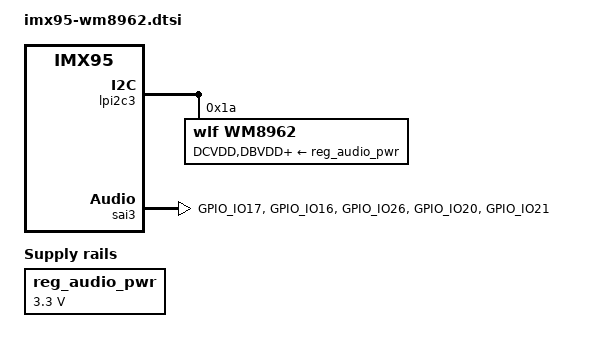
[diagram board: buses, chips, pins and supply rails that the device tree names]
&{/} {

	reg_audio_pwr: regulator-audio-pwr {
		compatible = "regulator-fixed";
		regulator-name = "audio-pwr";
		regulator-min-microvolt = <3300000>;
		regulator-max-microvolt = <3300000>;
	};

	sound-wm8962 {
		compatible = "fsl,imx-audio-wm8962x";
		model = "wm8962-audio";
		audio-cpu = <&sai3>;
		audio-codec = <&wm8962>;

		audio-routing =
			"Headphone Jack", "HPOUTL",
			"Headphone Jack", "HPOUTR",
			"Ext Spk", "SPKOUTL",
			"Ext Spk", "SPKOUTR",
			"AMIC", "MICBIAS",
			"IN3R", "AMIC",
			"IN1R", "AMIC";
	};
};

&lpi2c3 {
	#address-cells = <1>;
	#size-cells = <0>;

	wm8962: codec@1a {
		compatible = "wlf,wm8962";
		reg = <0x1a>;
		clocks = <&scmi_clk IMX95_CLK_SAI3>;
		DCVDD-supply = <&reg_audio_pwr>;
		DBVDD-supply = <&reg_audio_pwr>;
		AVDD-supply = <&reg_audio_pwr>;
		CPVDD-supply = <&reg_audio_pwr>;
		MICVDD-supply = <&reg_audio_pwr>;
		PLLVDD-supply = <&reg_audio_pwr>;
		SPKVDD1-supply = <&reg_audio_pwr>;
		SPKVDD2-supply = <&reg_audio_pwr>;
		gpio-cfg = <
			0x0000 /* 0:Default */
			0x0000 /* 1:Default */
			0x0000 /* 2:FN_DMICCLK */
			0x0000 /* 3:Default */
			0x0000 /* 4:FN_DMICCDAT */
			0x0000 /* 5:Default */
		>;
	};
};

&sai3 {
	#sound-dai-cells = <0>;
	pinctrl-names = "default";
	pinctrl-0 = <&pinctrl_sai3>;
	assigned-clocks = <&scmi_clk IMX95_CLK_AUDIOPLL1_VCO>,
			  <&scmi_clk IMX95_CLK_AUDIOPLL2_VCO>,
			  <&scmi_clk IMX95_CLK_AUDIOPLL1>,
			  <&scmi_clk IMX95_CLK_AUDIOPLL2>,
			  <&scmi_clk IMX95_CLK_SAI3>;
	assigned-clock-parents = <0>, <0>, <0>, <0>,
				 <&scmi_clk IMX95_CLK_AUDIOPLL1>;
	assigned-clock-rates = <3932160000>,
			       <3612672000>, <393216000>,
			       <361267200>, <12288000>;
	fsl,sai-mclk-direction-output;
	status = "okay";
};

&scmi_iomuxc {
	pinctrl_sai3: sai3grp {
		fsl,pins = <
			IMX95_PAD_GPIO_IO17__SAI3_MCLK				0x31e
			IMX95_PAD_GPIO_IO16__SAI3_TX_BCLK			0x31e
			IMX95_PAD_GPIO_IO26__SAI3_TX_SYNC			0x31e
			IMX95_PAD_GPIO_IO20__SAI3_RX_DATA_BIT0			0x31e
			IMX95_PAD_GPIO_IO21__SAI3_TX_DATA_BIT0			0x31e
		>;
	};

	pinctrl_wm8962: wm8961grp {
		fsl,pins = <
			/* Schematics says that it is CS/GPIO6 CODEC_INT *
			/* purpouse is unknown */
			IMX95_PAD_GPIO_IO22__GPIO2_IO_BIT22		0x31e
		>;
	};
};
